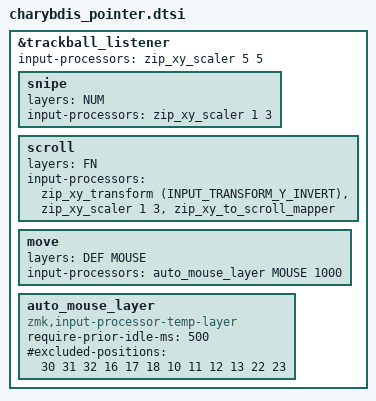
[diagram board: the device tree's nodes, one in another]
#include <input/processors.dtsi>
#include <dt-bindings/zmk/input_transform.h>

#define DEF 0
#define MOUSE 1
#define SYM 2
#define NUM 3
#define FN 4
#define GENSHIN 5 

&trackball_listener {
    /* base processor chain on all layers */
    input-processors = <&zip_xy_scaler 5 5>;

    snipe {
      layers = <NUM>;
      input-processors = <&zip_xy_scaler 1 3>;
    };

    scroll {
      layers = <FN>;
      input-processors = <&zip_xy_transform (INPUT_TRANSFORM_Y_INVERT)>, <&zip_xy_scaler 1 3>, <&zip_xy_to_scroll_mapper>;
    };

    move {
      layers = <DEF MOUSE>;
      input-processors = <&auto_mouse_layer MOUSE 1000>;
    };
 
  auto_mouse_layer: auto_mouse_layer {
    compatible = "zmk,input-processor-temp-layer";
    #input-processor-cells = <2>;
    require-prior-idle-ms = <500>;
    #excluded-positions = <30 31 32 16 17 18 10 11 12 13 22 23>;
  };    
  
};
